# STM32H5F4 register map
File version: 1.0
CPU: CM33 r0p0, little endian, MPU, FPU, 4 interrupt priority bits
Registers are 32-bit, read-write, reset 0x0 unless marked. A register's access mark holds for its fields unless they carry their own. Offsets are from the block's base; [hi:lo] are bit positions; {n}, {i} and the like mark numbered series.

## GPIOA — GPIOA address block description
Base 0x42020000
Same registers: GPIOA_S 0x52020000
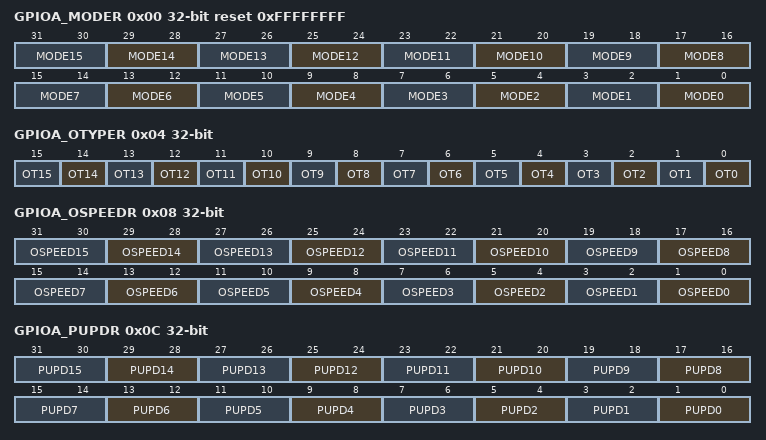
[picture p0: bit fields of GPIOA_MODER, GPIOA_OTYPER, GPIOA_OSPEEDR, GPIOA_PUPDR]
0x00 GPIOA_MODER reset 0xFFFFFFFF — GPIO port mode register
  [all] fields
    0=Input mode; 1=General purpose output mode; 2=Alternate function mode; 3=Analog mode (reset state)
  [2n+1:2n] MODE{n} (n=0..15) — Port x configuration I/O pin y
0x04 GPIOA_OTYPER — GPIO port output type register
  [all] fields
    0=Output push-pull (reset state); 1=Output open-drain
  [n] OT{n} (n=0..15) — Port x configuration I/O pin y
0x08 GPIOA_OSPEEDR — GPIO port output speed register
  [all] fields
    0=Low speed; 1=Medium speed; 2=High speed; 3=Very-high speed
  [2n+1:2n] OSPEED{n} (n=0..15) — Port x configuration I/O pin y
0x0C GPIOA_PUPDR — GPIO port pull-up/pull-down register
  [all] fields
    0=No pull-up, pull-down; 1=Pull-up; 2=Pull-down
  [2n+1:2n] PUPD{n} (n=0..15) — Port x configuration I/O pin y
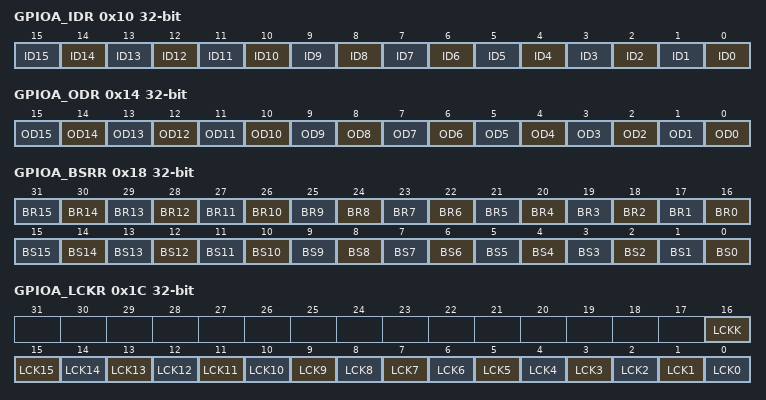
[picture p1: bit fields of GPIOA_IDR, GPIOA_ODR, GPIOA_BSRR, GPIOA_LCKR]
0x10 GPIOA_IDR ro (reset mask 0xFFFF0000) — GPIO port input data register
  [n] ID{n} (n=0..15) — Port x input data I/O pin y
0x14 GPIOA_ODR — GPIO port output data register
  [n] OD{n} (n=0..15) — Port output data I/O pin y
0x18 GPIOA_BSRR wo — GPIO port bit set/reset register
  [n+16] BR{n} (n=0..15) — Port x reset I/O pin y
    0=No action on the corresponding ODy bit; 1=Resets the corresponding ODy bit
  [n] BS{n} (n=0..15) — Port x set I/O pin y
    0=No action on the corresponding ODy bit; 1=Sets the corresponding ODy bit
0x1C GPIOA_LCKR — GPIO port configuration lock register
  [16] LCKK — Lock key
    0=Port configuration lock key not active; 1=Port configuration lock key active
  [n] LCK{n} (n=0..15) — Port x lock I/O pin y
    0=Port configuration not locked; 1=Port configuration locked
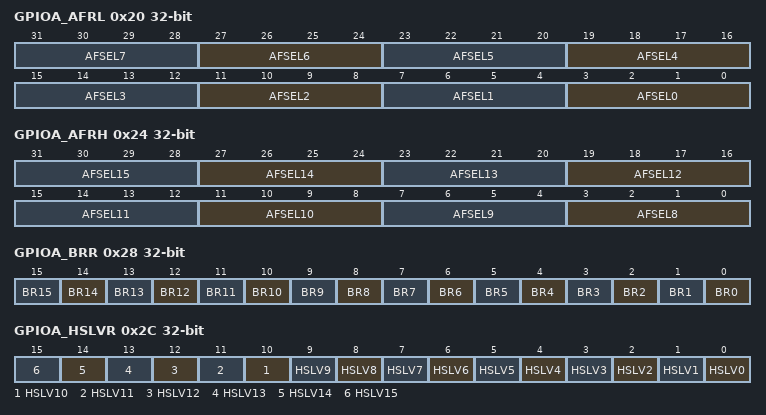
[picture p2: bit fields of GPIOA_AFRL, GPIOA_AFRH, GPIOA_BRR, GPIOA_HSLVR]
0x20 GPIOA_AFRL — GPIO alternate function low register
  [all] fields
    {v}=AF{v} (v=0..15)
  [4n+3:4n] AFSEL{n} (n=0..7) — Alternate function selection for port x I/O pin y
0x24 GPIOA_AFRH — GPIO alternate function high register
  [all] fields
    {v}=AF{v} (v=0..15)
  [4n-29:4n-32] AFSEL{n} (n=8..15) — Alternate function selection for port x I/O pin y
0x28 GPIOA_BRR wo — GPIO port bit reset register
  [all] fields
    0=No action on the corresponding ODy bit; 1=Reset the corresponding ODy bit
  [n] BR{n} (n=0..15) — Port x reset IO pin y
0x2C GPIOA_HSLVR — GPIO high-speed low-voltage register
  [all] fields
    0=I/O speed optimization disabled; 1=I/O speed optimization enabled
  [n] HSLV{n} (n=0..15) — Port x high-speed low-voltage configuration
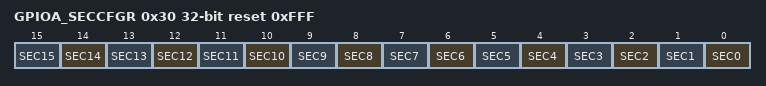
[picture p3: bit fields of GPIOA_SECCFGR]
0x30 GPIOA_SECCFGR reset 0xFFF — GPIO secure configuration register
  [all] fields
    0=The I/O pin is nonsecure; 1=The I/O pin is secure
  [n] SEC{n} (n=0..15) — I/O pin of Port x secure bit enable y

## GPIOB — GPIOB address block description
Base 0x42020400
Same registers: GPIOB_S 0x52020400
Registers as GPIOA (with GPIOA read as GPIOB).

## GPIOC — GPIOC address block description
Base 0x42020800
Same registers: GPIOC_S 0x52020800
Registers as GPIOA (with GPIOA read as GPIOC).

## GPIOD — GPIOD address block description
Base 0x42020C00
Same registers: GPIOD_S 0x52020C00
Registers as GPIOA (with GPIOA read as GPIOD).

## GPIOE — GPIOE address block description
Base 0x42021000
Same registers: GPIOE_S 0x52021000
Registers as GPIOA (with GPIOA read as GPIOE).

## GPIOF — GPIOF address block description
Base 0x42021400
Same registers: GPIOF_S 0x52021400
Registers as GPIOA (with GPIOA read as GPIOF).

## GPIOG — GPIOG address block description
Base 0x42021800
Same registers: GPIOG_S 0x52021800
Registers as GPIOA (with GPIOA read as GPIOG).

## GPIOH — GPIOH address block description
Base 0x42021C00
Same registers: GPIOH_S 0x52021C00
Registers as GPIOA (with GPIOA read as GPIOH).

## GPIOI — GPIOI address block description
Base 0x42022000
Same registers: GPIOI_S 0x52022000
Registers as GPIOA (with GPIOA read as GPIOI).

## GPIOJ — GPIOJ address block description
Base 0x42022400
Same registers: GPIOJ_S 0x52022400
Registers as GPIOA (with GPIOA read as GPIOJ).

## GPIOK — GPIOK address block description
Base 0x42022800
Same registers: GPIOK_S 0x52022800
Registers as GPIOA (with GPIOA read as GPIOK).
